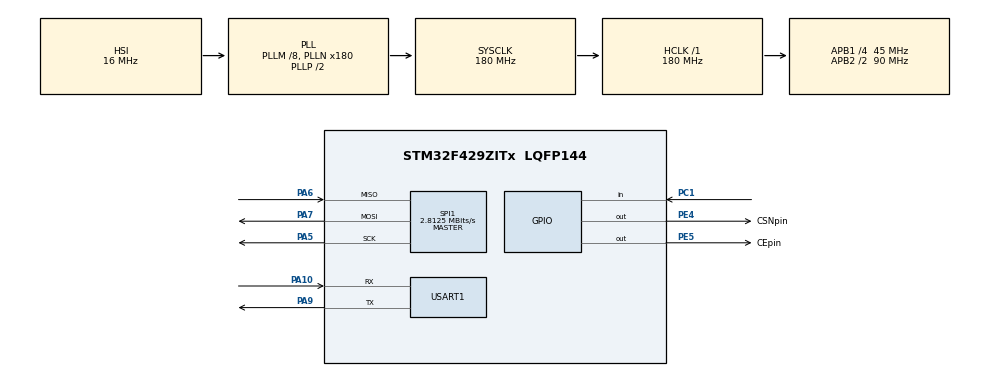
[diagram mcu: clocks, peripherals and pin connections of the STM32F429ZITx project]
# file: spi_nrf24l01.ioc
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Mcu.Family=STM32F4
Mcu.Name=STM32F429ZITx
Mcu.Package=LQFP144
NVIC.PriorityGroup=NVIC_PRIORITYGROUP_4
PA10.Mode=Asynchronous
PA10.Signal=USART1_RX
PA5.Mode=Full_Duplex_Master
PA5.Signal=SPI1_SCK
PA6.Mode=Full_Duplex_Master
PA6.Signal=SPI1_MISO
PA7.Mode=Full_Duplex_Master
PA7.Signal=SPI1_MOSI
PA9.Mode=Asynchronous
PA9.Signal=USART1_TX
PC1.Signal=GPIO_Input
PE4.GPIO_Label=CSNpin
PE4.Signal=GPIO_Output
PE5.GPIO_Label=CEpin
PE5.Signal=GPIO_Output
ProjectManager.HeapSize=0x200
ProjectManager.StackSize=0x400
ProjectManager.TargetToolchain=MDK-ARM V5
RCC.48MHZClocksFreq_Value=90000000
RCC.AHBFreq_Value=180000000
RCC.APB1CLKDivider=RCC_HCLK_DIV4
RCC.APB1Freq_Value=45000000
RCC.APB1TimFreq_Value=90000000
RCC.APB2CLKDivider=RCC_HCLK_DIV2
RCC.APB2Freq_Value=90000000
RCC.APB2TimFreq_Value=180000000
RCC.CortexFreq_Value=180000000
RCC.HCLKFreq_Value=180000000
RCC.HSE_VALUE=25000000
RCC.HSI_VALUE=16000000
RCC.LSE_VALUE=32768
RCC.PLLM=8
RCC.PLLN=180
RCC.SYSCLKFreq_VALUE=180000000
RCC.SYSCLKSource=RCC_SYSCLKSOURCE_PLLCLK
RCC.VCOOutputFreq_Value=360000000
SPI1.BaudRatePrescaler=SPI_BAUDRATEPRESCALER_32
SPI1.CalculateBaudRate=2.8125 MBits/s
SPI1.Direction=SPI_DIRECTION_2LINES
SPI1.Mode=SPI_MODE_MASTER
SPI1.VirtualType=VM_MASTER
USART1.VirtualMode=VM_ASYNC
board=custom

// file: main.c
/* USER CODE BEGIN Header */
/**
  ******************************************************************************
  * @file           : main.c
  * @brief          : Main program body
  ******************************************************************************
  * @attention
  *
  * <h2><center>&copy; Copyright (c) 2019 STMicroelectronics.
  * All rights reserved.</center></h2>
  *
  * This software component is licensed by ST under BSD 3-Clause license,
  * the "License"; You may not use this file except in compliance with the
  * License. You may obtain a copy of the License at:
  *                        opensource.org/licenses/BSD-3-Clause
  *
  ******************************************************************************
  */
/* USER CODE END Header */

#include "main.h"
#include "stm32f4xx_hal.h"
/* USER CODE BEGIN Includes */
#include "MY_NRF24.h"
/* USER CODE END Includes */

SPI_HandleTypeDef hspi1;

UART_HandleTypeDef huart1;

void SystemClock_Config(void);
static void MX_GPIO_Init(void);
static void MX_SPI1_Init(void);
static void MX_USART1_UART_Init(void);

/* USER CODE BEGIN 0 */
uint64_t Txpipeadrs = 0x0011223344AA;
char mytxdata[32] ="helloworld";

/* USER CODE END 0 */

int main(void)
{

  /* MCU Configuration--------------------------------------------------------*/

  /* Reset of all peripherals, Initializes the Flash interface and the Systick. */
  HAL_Init();

  /* Configure the system clock */
  SystemClock_Config();

  /* Initialize all configured peripherals */
  MX_GPIO_Init();
  MX_SPI1_Init();
  MX_USART1_UART_Init();
  /* USER CODE BEGIN 2 */
NRF24_begin(GPIOE, CSNpin_Pin, GPIO_PIN_5, hspi1);
nrf24_DebugUART_Init(huart1);

printRadioSettings();

//---------------transmit no acknowlegment--------
NRF24_stopListening();
NRF24_openWritingPipe(Txpipeadrs);
NRF24_setAutoAck(false);
NRF24_setChannel(52);
NRF24_setPayloadSize(32);

  /* USER CODE END 2 */

  /* Infinite loop */
  while (1)
  {
		NRF24_write(mytxdata, 32);
//if(NRF24_write(mytxdata, 32))
//
//{
//HAL_UART_Transmit(&huart1, (uint8_t *)"transmitted succesfully\r\n", strlen("transmitted succesfully\r\n"), 10);

//}

		HAL_Delay(1000);

  }
}

void SystemClock_Config(void)
{
  RCC_OscInitTypeDef RCC_OscInitStruct = {0};
  RCC_ClkInitTypeDef RCC_ClkInitStruct = {0};

  /** Configure the main internal regulator output voltage
  */
  __HAL_RCC_PWR_CLK_ENABLE();
  __HAL_PWR_VOLTAGESCALING_CONFIG(PWR_REGULATOR_VOLTAGE_SCALE1);
  /** Initializes the CPU, AHB and APB busses clocks
  */
  RCC_OscInitStruct.OscillatorType = RCC_OSCILLATORTYPE_HSI;
  RCC_OscInitStruct.HSIState = RCC_HSI_ON;
  RCC_OscInitStruct.HSICalibrationValue = RCC_HSICALIBRATION_DEFAULT;
  RCC_OscInitStruct.PLL.PLLState = RCC_PLL_ON;
  RCC_OscInitStruct.PLL.PLLSource = RCC_PLLSOURCE_HSI;
  RCC_OscInitStruct.PLL.PLLM = 8;
  RCC_OscInitStruct.PLL.PLLN = 180;
  RCC_OscInitStruct.PLL.PLLP = RCC_PLLP_DIV2;
  RCC_OscInitStruct.PLL.PLLQ = 4;
  if (HAL_RCC_OscConfig(&RCC_OscInitStruct) != HAL_OK)
  {
    Error_Handler();
  }
  /** Activate the Over-Drive mode
  */
  if (HAL_PWREx_EnableOverDrive() != HAL_OK)
  {
    Error_Handler();
  }
  /** Initializes the CPU, AHB and APB busses clocks
  */
  RCC_ClkInitStruct.ClockType = RCC_CLOCKTYPE_HCLK|RCC_CLOCKTYPE_SYSCLK
                              |RCC_CLOCKTYPE_PCLK1|RCC_CLOCKTYPE_PCLK2;
  RCC_ClkInitStruct.SYSCLKSource = RCC_SYSCLKSOURCE_PLLCLK;
  RCC_ClkInitStruct.AHBCLKDivider = RCC_SYSCLK_DIV1;
  RCC_ClkInitStruct.APB1CLKDivider = RCC_HCLK_DIV4;
  RCC_ClkInitStruct.APB2CLKDivider = RCC_HCLK_DIV2;

  if (HAL_RCC_ClockConfig(&RCC_ClkInitStruct, FLASH_LATENCY_5) != HAL_OK)
  {
    Error_Handler();
  }
}

static void MX_SPI1_Init(void)
{

  /* SPI1 parameter configuration*/
  hspi1.Instance = SPI1;
  hspi1.Init.Mode = SPI_MODE_MASTER;
  hspi1.Init.Direction = SPI_DIRECTION_2LINES;
  hspi1.Init.DataSize = SPI_DATASIZE_8BIT;
  hspi1.Init.CLKPolarity = SPI_POLARITY_LOW;
  hspi1.Init.CLKPhase = SPI_PHASE_1EDGE;
  hspi1.Init.NSS = SPI_NSS_SOFT;
  hspi1.Init.BaudRatePrescaler = SPI_BAUDRATEPRESCALER_32;
  hspi1.Init.FirstBit = SPI_FIRSTBIT_MSB;
  hspi1.Init.TIMode = SPI_TIMODE_DISABLE;
  hspi1.Init.CRCCalculation = SPI_CRCCALCULATION_DISABLE;
  hspi1.Init.CRCPolynomial = 10;
  if (HAL_SPI_Init(&hspi1) != HAL_OK)
  {
    Error_Handler();
  }

}

static void MX_USART1_UART_Init(void)
{

  huart1.Instance = USART1;
  huart1.Init.BaudRate = 115200;
  huart1.Init.WordLength = UART_WORDLENGTH_8B;
  huart1.Init.StopBits = UART_STOPBITS_1;
  huart1.Init.Parity = UART_PARITY_NONE;
  huart1.Init.Mode = UART_MODE_TX_RX;
  huart1.Init.HwFlowCtl = UART_HWCONTROL_NONE;
  huart1.Init.OverSampling = UART_OVERSAMPLING_16;
  if (HAL_UART_Init(&huart1) != HAL_OK)
  {
    Error_Handler();
  }

}

static void MX_GPIO_Init(void)
{
  GPIO_InitTypeDef GPIO_InitStruct = {0};

  /* GPIO Ports Clock Enable */
  __HAL_RCC_GPIOE_CLK_ENABLE();
  __HAL_RCC_GPIOC_CLK_ENABLE();
  __HAL_RCC_GPIOA_CLK_ENABLE();

  /*Configure GPIO pin Output Level */
  HAL_GPIO_WritePin(GPIOE, CSNpin_Pin|CEpin_Pin, GPIO_PIN_RESET);

  /*Configure GPIO pins : CSNpin_Pin CEpin_Pin */
  GPIO_InitStruct.Pin = CSNpin_Pin|CEpin_Pin;
  GPIO_InitStruct.Mode = GPIO_MODE_OUTPUT_PP;
  GPIO_InitStruct.Pull = GPIO_NOPULL;
  GPIO_InitStruct.Speed = GPIO_SPEED_FREQ_LOW;
  HAL_GPIO_Init(GPIOE, &GPIO_InitStruct);

  /*Configure GPIO pin : PC1 */
  GPIO_InitStruct.Pin = GPIO_PIN_1;
  GPIO_InitStruct.Mode = GPIO_MODE_INPUT;
  GPIO_InitStruct.Pull = GPIO_NOPULL;
  HAL_GPIO_Init(GPIOC, &GPIO_InitStruct);

}

void Error_Handler(void)
{
}

/************************ (C) COPYRIGHT STMicroelectronics *****END OF FILE****/
